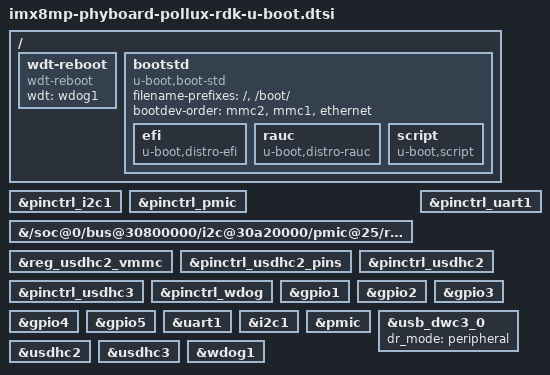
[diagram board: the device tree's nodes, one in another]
// SPDX-License-Identifier: GPL-2.0-or-later
/*
 * Copyright (C) 2020 PHYTEC Messtechnik GmbH
 * Author: Teresa Remmet <t.remmet@phytec.de>
 */

#include "imx8mp-u-boot.dtsi"

/ {
	wdt-reboot {
		compatible = "wdt-reboot";
		wdt = <&wdog1>;
		bootph-pre-ram;
	};

	bootstd {
		bootph-verify;
		compatible = "u-boot,boot-std";

		filename-prefixes = "/", "/boot/";
		bootdev-order = "mmc2", "mmc1", "ethernet";

		efi {
			compatible = "u-boot,distro-efi";
		};

		rauc {
			compatible = "u-boot,distro-rauc";
		};

		script {
			compatible = "u-boot,script";
		};
	};
};

&pinctrl_i2c1 {
	bootph-all;
};

&pinctrl_pmic {
	bootph-all;
};

&{/soc@0/bus@30800000/i2c@30a20000/pmic@25/regulators} {
	bootph-all;
};

&reg_usdhc2_vmmc {
	bootph-pre-ram;
};

&pinctrl_uart1 {
	bootph-pre-ram;
};

&pinctrl_usdhc2_pins {
	bootph-pre-ram;
};

&pinctrl_usdhc2 {
	bootph-pre-ram;
};

&pinctrl_usdhc3 {
	bootph-pre-ram;
};

&pinctrl_wdog {
	bootph-pre-ram;
};

&gpio1 {
	bootph-pre-ram;
};

&gpio2 {
	bootph-pre-ram;
};

&gpio3 {
	bootph-pre-ram;
};

&gpio4 {
	bootph-pre-ram;
};

&gpio5 {
	bootph-pre-ram;
};

&uart1 {
	bootph-pre-ram;
};

&i2c1 {
	bootph-all;
};

&pmic {
	bootph-all;
};

&usb_dwc3_0 {
	dr_mode = "peripheral";
};

&usdhc2 {
	bootph-pre-ram;
	/*
	 * LDO5 output depends on SD2_VSEL, but no way to read back SD2_VSEL
	 * when using SDHC controller VSELECT to control SD2_VSEL. So drop
	 * vqmmc-supply to avoid fsl_esdhc_imx read back wrong voltage.
	 */
	/delete-property/ vqmmc-supply;
};

&usdhc3 {
	bootph-pre-ram;
};

&wdog1 {
	bootph-pre-ram;
};
